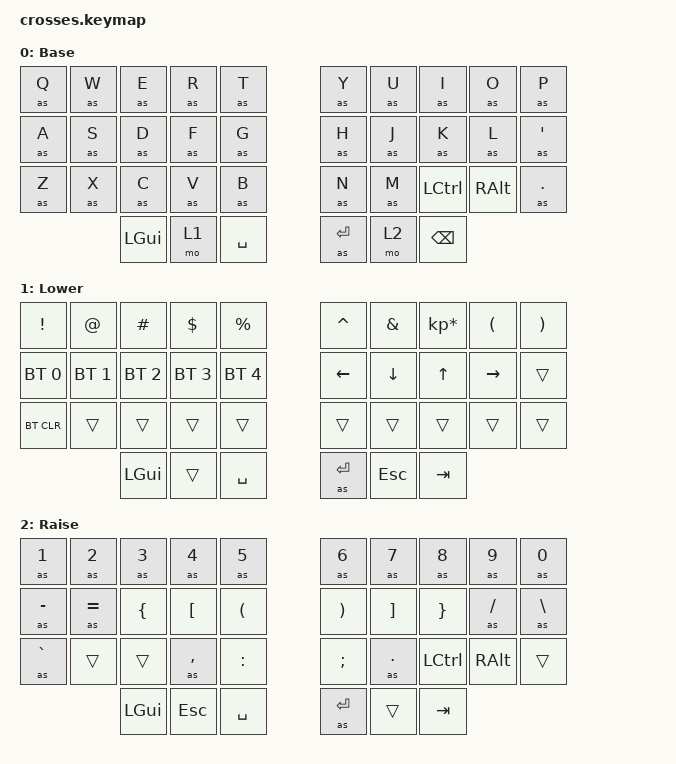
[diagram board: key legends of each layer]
#include <behaviors.dtsi>
#include <dt-bindings/zmk/bt.h>
#include <dt-bindings/zmk/keys.h>
#include <dt-bindings/zmk/outputs.h>
#include <dt-bindings/zmk/pointing.h>

/ {
    chosen {
        zmk,physical-layout = &gggw_crosses_36_layout;
    };
    behaviors {
        as: auto_shift {
            compatible = "zmk,behavior-hold-tap";
            #binding-cells = <2>;
            tapping_term_ms = <200>;
            quick_tap_ms = <0>;
            flavor = "tap-preferred";
            bindings = <&kp>, <&kp>;
        };
    };
    keymap {
        compatible = "zmk,keymap";
        default_layer {
            // -----------------------------------------------------------------------------------------
            // |  Q  |  W  |  E  |  R  |  T  |     |  Y  |  U   |  I   |  O   | P |
            // |  A  |  S  |  D  |  F  |  G  |     |  H  |  J   |  K   |  L   | ' | 
            // |  Z  |  X  |  C  |  V  |  B  |     |  N  |  M   | CTRL | META | . |
            //             | GUI | LWR | SPC |     | ENT | RSE  | BSPC |
            display-name = "Base";
            bindings = <
            &as Q &as W &as E &as R &as T     &as Y   &as U  &as I     &as O     &as P
            &as A &as S &as D &as F &as G     &as H   &as J  &as K     &as L     &as SQT
            &as Z &as X &as C &as V &as B     &as N   &as M  &kp LCTL  &kp RALT  &as DOT
                    &kp LGUI &mo 1 &kp SPACE     &as RET &mo 2  &kp BSPC
            >;
        };

        lower_layer {
            // -----------------------------------------------------------------------------------------
            // | !     |  @  |  #  |  $  |  %  |     |  ^  |  &  |  *  |  (  |  )  |
            // | BT1   | BT2 | BT3 | BT4 | BT5 |     | LFT | DWN |  UP | RGT |     |
            // | BTCLR |     |     |     |     |     |     |     |     |     |     |
            //               | GUI |     | SPC |     | ENT | ESC | TAB |
            display-name = "Lower";
            bindings = <
                &kp EXCL     &kp AT       &kp HASH     &kp DLLR     &kp PRCNT        &kp CARET &kp AMPS  &kp KP_MULTIPLY &kp LPAR  &kp RPAR
                &bt BT_SEL 0 &bt BT_SEL 1 &bt BT_SEL 2 &bt BT_SEL 3 &bt BT_SEL 4     &kp LEFT  &kp DOWN  &kp UP          &kp RIGHT &trans 
                &bt BT_CLR   &trans       &trans       &trans       &trans           &trans    &trans    &trans          &trans    &trans 
                                        &kp LGUI     &trans       &kp SPACE          &as RET   &kp ESC   &kp TAB
            >;
        };

        raise_layer {
            // -----------------------------------------------------------------------------------------
            // | 1! |  2@ |  3# |  4$ |  5% |     |  6^ |  7& |  8* |  9(  |  0)  |
            // | -_ |  =+ |  {  |  [  |  (  |     |  )  |  ]  |  }  |  /?  |  \|  |
            // | `~ |     |     |  ,< |  :  |     |  ;  |  .> | CTRL| META |      |
            //            | GUI | ESC | SPC |     | ENT |     | TAB |
            display-name = "Raise";
            bindings = <
                &as N1    &as N2    &as N3    &as N4    &as N5        &as N6    &as N7    &as N8    &as N9   &as N0
                &as MINUS &as EQUAL &kp LBRC  &kp LBKT  &kp LPAR      &kp RPAR  &kp RBKT  &kp RBRC  &as FSLH &as BSLH
                &as GRAVE &trans    &trans    &as COMMA &kp COLON     &kp SEMI  &as DOT   &kp LCTRL &kp RALT &trans
                                    &kp LGUI  &kp ESC   &kp SPACE     &as RET   &trans    &kp TAB
                                        >;
        };

    };
};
